# nrf5340_application register map
Vendor: Nordic Semiconductor; Series: nrf53; File version: 1
CPU: CM33 r0p4, little endian, MPU, FPU, 3 interrupt priority bits, 69 interrupts
Registers are 32-bit, read-write, reset 0x0 unless marked. A register's access mark holds for its fields unless they carry their own. Offsets are from the block's base; [hi:lo] are bit positions.

## CC_HOST_RGF_S — CRYPTOCELL HOST register interface
Base 0x50845000; alternate view of CC_AES_S
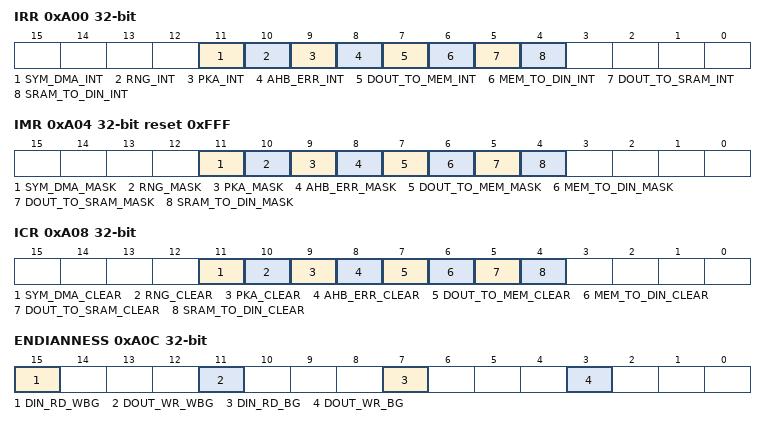
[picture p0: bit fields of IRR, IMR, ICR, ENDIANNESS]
0xA00 IRR ro — Interrupt request register. Each bit of this register holds the interrupt status of a single interrupt source. If corresponding IMR bit is unmasked, an interrupt is generated.
  [11] SYM_DMA_INT — The symmetric engine DMA completed interrupt status.
  [10] RNG_INT — The RNG interrupt status.
  [9] PKA_INT — The PKA end of operation interrupt status.
  [8] AHB_ERR_INT — The AHB error interrupt status.
  [7] DOUT_TO_MEM_INT — The DOUT to memory DMA done interrupt status. This interrupt is asserted when all data was delivered from DOUT buffer to memory.
  [6] MEM_TO_DIN_INT — The memory to DIN DMA done interrupt status. This interrupt is asserted when all data was delivered from memory to DIN buffer.
  [5] DOUT_TO_SRAM_INT — The DOUT to RNG SRAM DMA done interrupt status. This interrupt is asserted when all data was delivered from DOUT buffer to RNG SRAM.
  [4] SRAM_TO_DIN_INT — The RNG SRAM to DIN DMA done interrupt status. This interrupt is asserted when all data was delivered from RNG SRAM to DIN buffer.
0xA04 IMR reset 0xFFF — Interrupt mask register. Each bit of this register holds the mask of a single interrupt source.
  [11] SYM_DMA_MASK — The symmetric engine DMA completed interrupt mask.
    0=IRQEnable (Do not mask the symmetric engine DMA completed interrupt i.e. interrupt is generated); 1=IRQDisable (Mask the symmetric engine DMA completed interrupt i.e. no interrupt is generated)
  [10] RNG_MASK — The RNG interrupt mask.
    0=IRQEnable (Do not mask RNG interrupt i.e. interrupt is generated); 1=IRQDisable (Mask RNG interrupt i.e. no interrupt is generated)
  [9] PKA_MASK — The PKA end of operation interrupt mask.
    0=IRQEnable (Do not mask PKA end of operation interrupt i.e. interrupt is generated); 1=IRQDisable (Mask PKA end of operation interrupt i.e. no interrupt is generated)
  [8] AHB_ERR_MASK — The AHB error interrupt mask.
    0=IRQEnable (Do not mask AHB error interrupt i.e. interrupt is generated); 1=IRQDisable (Mask AHB error interrupt i.e. no interrupt is generated)
  [7] DOUT_TO_MEM_MASK — The DOUT to memory DMA done interrupt mask.
    0=IRQEnable (Do not mask DOUT to memory DMA done interrupt i.e. interrupt is generated); 1=IRQDisable (Mask DOUT to memory DMA done interrupt i.e. no interrupt is generated)
  [6] MEM_TO_DIN_MASK — The memory to DIN DMA done interrupt mask.
    0=IRQEnable (Do not mask memory to DIN DMA done interrupt i.e. interrupt is generated); 1=IRQDisable (Mask memory to DIN DMA done interrupt i.e. no interrupt is generated)
  [5] DOUT_TO_SRAM_MASK — The DOUT to RNG SRAM DMA done interrupt mask.
    0=IRQEnable (Do not mask DOUT to RNG SRAM DMA done interrupt i.e. interrupt is generated); 1=IRQDisable (Mask DOUT to RNG SRAM DMA done interrupt i.e. no interrupt is generated)
  [4] SRAM_TO_DIN_MASK — The RNG SRAM to DIN DMA done interrupt mask.
    0=IRQEnable (Do not mask RNG SRAM to DIN DMA done interrupt i.e. interrupt is generated); 1=IRQDisable (Mask RNG SRAM to DIN DMA done interrupt i.e. no interrupt is generated)
0xA08 ICR wo — Interrupt clear register. Writing a 1 bit into a field in this register will clear the corresponding bit in IRR.
  [11] SYM_DMA_CLEAR — The symmetric engine DMA completed interrupt clear.
  [10] RNG_CLEAR — The RNG interrupt clear. Register RNG_ISR in the RNG engine must be cleared before this interrupt can be cleared.
  [9] PKA_CLEAR — The PKA end of operation interrupt clear.
  [8] AHB_ERR_CLEAR — The AHB error interrupt clear.
  [7] DOUT_TO_MEM_CLEAR — The DOUT to memory DMA done interrupt clear.
  [6] MEM_TO_DIN_CLEAR — The memory to DIN DMA done interrupt clear.
  [5] DOUT_TO_SRAM_CLEAR — The DOUT to RNG SRAM DMA done interrupt clear.
  [4] SRAM_TO_DIN_CLEAR — The RNG SRAM to DIN DMA done interrupt clear.
0xA0C ENDIANNESS — This register defines the endianness of the Host-accessible registers, and can only be written once.
  [15] DIN_RD_WBG — DIN read word endianness.
    0=LittleEndian (Configure DIN read word as little-endian); 1=BigEndian (Configure DIN read word as big-endian)
  [11] DOUT_WR_WBG — DOUT write word endianness.
    0=LittleEndian (Configure DOUT write word as little-endian); 1=BigEndian (Configure DOUT write word as big-endian)
  [7] DIN_RD_BG — DIN read endianness.
    0=LittleEndian (Configure DIN read as little-endian); 1=BigEndian (Configure DIN read as big-endian)
  [3] DOUT_WR_BG — DOUT write endianness.
    0=LittleEndian (Configure DOUT write as little-endian); 1=BigEndian (Configure DOUT write as big-endian)
0xA24 HOST_SIGNATURE ro reset 0x10E00000 — This register holds the CRYPTOCELL subsystem signature. See reset value.
  [31:0] VALUE — Fixed-value identification signature used by host driver to verify CRYPTOCELL presence at this address.
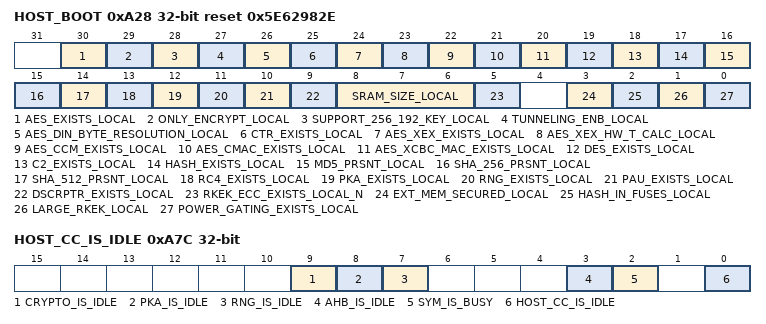
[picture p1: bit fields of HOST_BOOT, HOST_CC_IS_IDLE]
0xA28 HOST_BOOT ro reset 0x5E62982E — Hardware configuration of the CRYPTOCELL subsystem. Reset value holds the supported features.
  [30] AES_EXISTS_LOCAL — If this flag is set, the AES engine is present
  [29] ONLY_ENCRYPT_LOCAL — If this flag is set, the AES engine only support encryption
  [28] SUPPORT_256_192_KEY_LOCAL — If this flag is set, the AES engine supports 192/256 bits key sizes
  [27] TUNNELING_ENB_LOCAL — If this flag is set, the AES engine supports tunneling operations
  [26] AES_DIN_BYTE_RESOLUTION_LOCAL — If this flag is set, the AES engine data input support byte size resolution
  [25] CTR_EXISTS_LOCAL — If this flag is set, AES CTR mode is supported
  [24] AES_XEX_EXISTS_LOCAL — If this flag is set, AES XEX mode is supported
  [23] AES_XEX_HW_T_CALC_LOCAL — If this flag is set, AES XEX mode T-value calculation in HW is supported
  [22] AES_CCM_EXISTS_LOCAL — If this flag is set, AES CCM mode is supported
  [21] AES_CMAC_EXISTS_LOCAL — If this flag is set, AES CMAC mode is supported
  [20] AES_XCBC_MAC_EXISTS_LOCAL — If this flag is set, AES XCBC-MAC mode is supported
  [19] DES_EXISTS_LOCAL — If this flag is set, the DES engine is present
  [18] C2_EXISTS_LOCAL — If this flag is set, the C2 engine is present
  [17] HASH_EXISTS_LOCAL — If this flag is set, the HASH engine is present
  [16] MD5_PRSNT_LOCAL — If this flag is set, the HASH engine supports MD5
  [15] SHA_256_PRSNT_LOCAL — If this flag is set, the HASH engine supports SHA256
  [14] SHA_512_PRSNT_LOCAL — If this flag is set, the HASH engine supports SHA512
  [13] RC4_EXISTS_LOCAL — If this flag is set, the RC4 engine is present
  [12] PKA_EXISTS_LOCAL — If this flag is set, the PKA engine is present
  [11] RNG_EXISTS_LOCAL — If this flag is set, the RNG engine is present
  [10] PAU_EXISTS_LOCAL — If this flag is set, PAU is supported
  [9] DSCRPTR_EXISTS_LOCAL — If this flag is set, Descriptors are supported
  [8:6] SRAM_SIZE_LOCAL — SRAM size
  [5] RKEK_ECC_EXISTS_LOCAL_N — If this flag is set, RKEK ECC is supported
  [3] EXT_MEM_SECURED_LOCAL — If this flag is set, external secure memory is supported
  [2] HASH_IN_FUSES_LOCAL — If this flag is set, HASH in fuses is supported
  [1] LARGE_RKEK_LOCAL — If this flag is set, large RKEK is supported
  [0] POWER_GATING_EXISTS_LOCAL — If this flag is set, full power gating is implemented
0xA7C HOST_CC_IS_IDLE ro — Idle state register for the CRYPTOCELL subsystem.
  [9] CRYPTO_IS_IDLE — Cryptographic flow idle state.
    0=Busy (Cryptographic flow busy.); 1=Idle (Cryptographic flow idle.)
  [8] PKA_IS_IDLE — PKA engine idle state.
    0=Busy (PKA engine busy.); 1=Idle (PKA engine idle.)
  [7] RNG_IS_IDLE — RNG engine idle state.
    0=Busy (RNG engine busy.); 1=Idle (RNG engine idle.)
  [3] AHB_IS_IDLE — AHB state machine idle state.
    0=Busy (AHB state machine busy.); 1=Idle (AHB state machine idle.)
  [2] SYM_IS_BUSY — Symmetric flow busy state.
    1=Busy (Symmetric flow busy.); 0=Idle (Symmetric flow idle.)
  [0] HOST_CC_IS_IDLE — CRYPTOCELL idle state.
    0=Busy (CRYPTOCELL subsystem busy.); 1=Idle (CRYPTOCELL subsystem idle.)
0xA80 HOST_POWERDOWN — This register start the power-down sequence.
  [0] HOST_POWERDOWN — Power down enable register.
